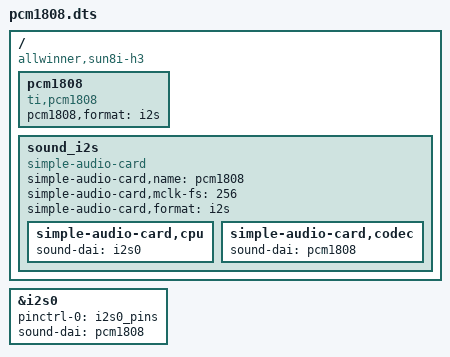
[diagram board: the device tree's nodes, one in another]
/dts-v1/;
/plugin/;

/ {
	compatible = "allwinner,sun8i-h3";

 	fragment@0 { 
 		target-path = "/"; 
 		__overlay__ { 
			pcm1808: pcm1808 {
			#sound-dai-cells = <0>;
			compatible = "ti,pcm1808";
			pcm1808,format = "i2s";
			};
 		}; 
 	}; 

	fragment@1 {
		target = <&i2s0>;
		__overlay__ {
			status = "okay";
			pinctrl-0 = <&i2s0_pins>;
			sound-dai = <&pcm1808>;
			pinctrl-names = "default";
		};
	};

	fragment@2 {
		target-path = "/";
		__overlay__ {
			sound_i2s {
				compatible = "simple-audio-card";
				simple-audio-card,name = "pcm1808";
				simple-audio-card,mclk-fs = <256>;
				simple-audio-card,format = "i2s";
		                status = "okay";

				simple-audio-card,cpu {
					sound-dai = <&i2s0>;
				};

				simple-audio-card,codec {
					sound-dai = <&pcm1808>;
				};
			};
		};
	};
};
